# cslr_pllc_001 register map
Vendor: Texas Instruments
Peripheral module from a debugger description file.
Registers are 32-bit, access per field, reset 0x0 unless marked. A register's access mark holds for its fields unless they carry their own. Offsets are as the file gives them; lines under a group give offsets from that group; [hi:lo] are bit positions; {n}, {i} and the like mark numbered series; 'fields as' and 'values as' point back to an identical list; <NAME> marks a mode.

## PLLC — This module propagates reset and clocks to the device
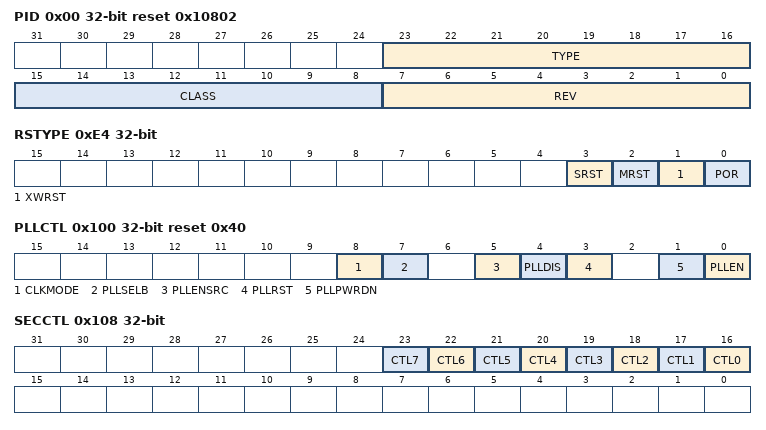
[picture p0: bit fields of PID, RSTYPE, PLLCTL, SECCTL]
0x00 PID ro reset 0x10802 — Contains peripheral ID and revision information
  [23:16] TYPE — Peripheral Type: 0x01 to identify as PLLCTRL
  [15:8] CLASS — Peripheral Class: 0x08
  [7:0] REV — Peripheral Revision
0xE0 FUSERR ro — Stores error code from fusefarm
  [4:0] ERR — Fusefarm Error. Actual default value depends on fusefarm error
0xE4 RSTYPE ro — Latches cause of the last reset. Although the reset value of all bits are 0, after coming out of reset, one bit will be set to one to indicate cause of reset. Some bits may not be doc'd to users.
  [all] fields
    0=NO; 1=YES
  [3] SRST — If 1, means that system reset was the last reset to occur that is of highest priority
  [2] MRST — If 1, means that maximum reset was the reset to occur that is of highest priority
  [1] XWRST — If 1, means that external warm reset was the last reset to occur that is of highest priority
  [0] POR — If 1, means that power on reset was the last reset to occur that is of highest priority
0xE8 RSTDEF — Defines the operation caused by external warm reset pin xwrst_pi_n. May not be documented to users.
  [0] XWFUNC rw — External Warm Reset Definition; May not be documented to users
    0=NORM (Normal mode. External warm reset causes xwrst operation); 1=FAST (Fast mode. External warm reset causes system reset (srst) operation)
0x100 PLLCTL reset 0x40 — Controls PLL operations. Only document necessary bits to users
  [8] CLKMODE rw — Reference Clock Selection; Actual default determined by module tieoff. May lock default value and doc as _RESV to users
    0=OSCIN (Internal oscillator); 1=CLKIN (CLKIN square wave)
  [7] PLLSELB rw — PLL Selection. Actual default determined by module tieoff. May lock default value and doc as _RESV to users
    0=PLLA (PLL A is selected. PLL B in power down); 1=PLLB (PLL B is selected. PLL A in power down)
  [5] PLLENSRC rw — PLLEN mux control source. Actual default determined by module tieoff. May lock default value and doc as _RESV to users
    0=REGBIT (PLLEN mux is controlled by PLLCTL.PLLEN bit); 1=PORT (PLLEN mux is controlled by input pllen_pi)
  [4] PLLDIS rw — Asserts DISABLE to PLL if supported. Actual default determined by module tieoff. If not supported, do not document to users
    0=NO (PLL disable de-asserted); 1=YES (PLL disable asserted)
  [3] PLLRST rw — Asserts RESET to PLL if supported. Actual default determined by module tieoff. If not supported, do not document to users
    0=NO (PLL reset not asserted); 1=YES (PLL reset asserted)
  [1] PLLPWRDN rw — PLL Power down. Actual default determined by module tieoff
    0=NO (PLL operation); 1=YES (PLL power down)
  [0] PLLEN rw — PLL Mode Enable
    0=BYPASS (Bypass mode); 1=PLL (PLL mode, not bypassed)
0x104 OCSEL — Controls the clock that outputs onto OBSCLK. May not need to document to users
  [4:0] OCSRC rw — OBSCLK source. Actual default determined by module tieoff. May not document this bit to users. Even if document may not document all options.
0x108 SECCTL — Extra PLL controls. May not need to document all bits (or the entire register) to users
  [n+16] CTL{n} rw (n=0..7) — PLL Control output. Actual default determined by module tieoff. Maybe documented with more precise bit field name to control a specific PLL
0x110 PLLM — PLL Multiplier Control
  [5:0] PLLM rw — PLL Multiplier Select. Actual default determined by module tieoff. May only document subset to users based on PLL multiply ratios supported
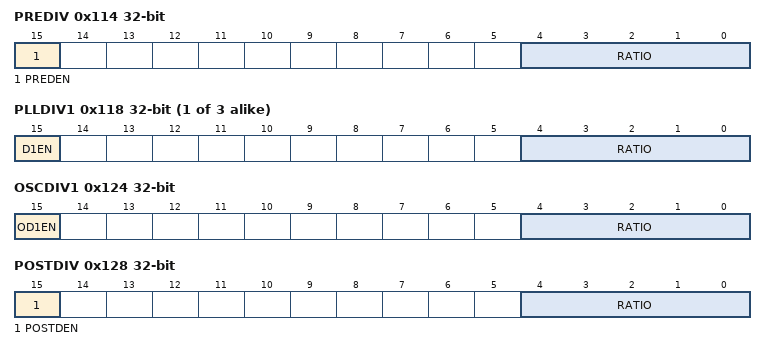
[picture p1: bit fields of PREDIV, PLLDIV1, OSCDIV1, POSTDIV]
0x114 PREDIV — PLL Pre-Divider control. Do not document if Pre-Divider is not implemented
  [15] PREDEN rw — Pre-Divider Enable. Actual default determined by module tieoff.
    0=DISABLE (Pre-div disabled); 1=ENABLE (Pre-div enabled)
  [4:0] RATIO rw — PLL Pre-divider ratio. Actual default determined by module tieoff. May lock default and make bit R only
{0x114+4i} PLLDIV{i} (i=1..3) — Divider {i} control--divider for SYSCLK{i}. Only document if this sysclk exists
  [15] D{i}EN rw — Divider Enable. Actual default determined by module tieoff. May lock default and make bit R only
    0=DISABLE; 1=ENABLE
  [4:0] RATIO rw — Divider ratio. Actual default determined by module tieoff. May lock default and make bit R only
0x124 OSCDIV1 — Oscillator Divider control--divider for OBSCLK functional clock. Only document if this clock exists
  [15] OD1EN rw — Oscillator Divider OD1 enable. Actual default determined by module tieoff
    0=DISABLE; 1=ENABLE
  [4:0] RATIO rw — Divider ratio. Actual default determined by module tieoff.
0x128 POSTDIV — Post-Divider control. Do not document if divider does not exist
  [15] POSTDEN rw — Post-Divider enable. Actual default determined by module tieoff
    0=DISABLE; 1=ENABLE
  [4:0] RATIO rw — Divider ratio. Actual default determined by module tieoff. May lock default and make bit R only
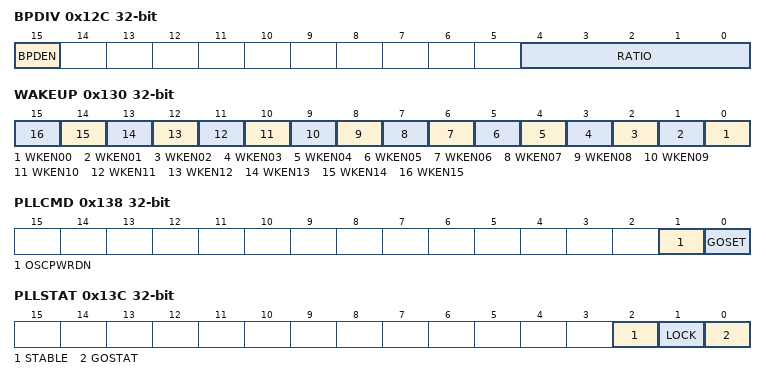
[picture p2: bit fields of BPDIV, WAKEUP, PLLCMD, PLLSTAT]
0x12C BPDIV — bypass divider control--divider for SYSCLKBP. Do not document if clock does not exist
  [15] BPDEN rw — Bypass Divider Enable. Actual default determined by module tieoff
    0=DISABLE; 1=ENABLE
  [4:0] RATIO rw — Divider ratio. Actual default determined by module tieoff.
0x130 WAKEUP — controls events that can wakeup device from oscillator power down. May not document all bits (or entire register) to users.
  [all] fields
    0=DISABLE (pin can't cause wakeup); 1=ENABLE (high on pin can cause wakeup)
  [n] WKEN{n:02} rw (n=0..15) — Wakeup Enable. Input wakeupin{n:02} can wake up device from osc power down.
0x138 PLLCMD — contains command bits for various operations. Writes of 1 initiates command. Writes of 0 clear the bit but have no effect. May not document all bits
  [1] OSCPWRDN rw — Oscillator Power Down Command. May not document if not supported by device
    0=CLRBIT (Clear bit (no effect)); 1=SET (Oscillator Power Down)
  [0] GOSET rw — GO bit for SYSCLKx phase alignment
    0=CLRBIT (Clear bit (no effect)); 1=SET (Phase alignment)
0x13C PLLSTAT ro — shows PLLCTRL status. May not need to document all bits
  [2] STABLE — OSC counter done, oscillator assumed to be stable. By the time device comes out of reset, this bit should become 1. May not need to document
    0=NO; 1=YES
  [1] LOCK — PLL Core Status. If supported, reflects if PLL is locked. Do not document if not supported by PLL
    0=NO; 1=YES
  [0] GOSTAT — Status of GO operation. If 1, indicates GO operation in progress.
    0=NONE; 1=INPROG
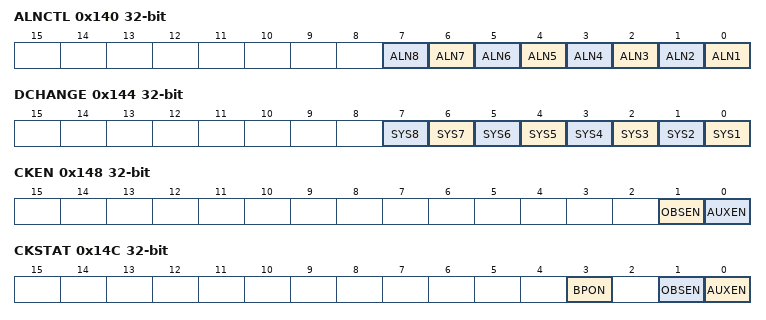
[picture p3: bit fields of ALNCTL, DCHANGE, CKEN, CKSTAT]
0x140 ALNCTL — Indicates which SYSCLKs need to be aligned for proper device operation. May lock defaults and make register R only. Actual default determined by module tieoff. Only document necessary bits
  [all] fields
    0=NO; 1=YES
  [n-1] ALN{n} rw (n=1..8) — SYSCLK{n} needs to be aligned to others selected in this register
0x144 DCHANGE ro — Indicates if SYSCLK divide ratio has been modified. Only document bit if the respective SYSCLK is implemented.
  [all] fields
    0=NO (ratio not modified); 1=YES (ratio modified)
  [n-1] SYS{n} (n=1..8) — SYSCLK{n} divide ratio is modified
0x148 CKEN — clock enable control for miscellaneous output clocks. Only document necessary bits to customers
  [1] OBSEN rw — OBSCLK Enable. Actual default determined by tieoff. May not document to users
    0=DISABLE; 1=ENABLE
  [0] AUXEN rw — AUXCLK enable. Actual default determined by tieoff. Only document if clk exists
    0=DISABLE; 1=ENABLE
0x14C CKSTAT ro — Clock status for all clocks except SYSCLKx. Only document necessary bits to users
  [all] fields
    0=OFF; 1=ON
  [3] BPON — SYSCLKBP on status. Actual default determined by tieoff. Only document if clock exists
  [1] OBSEN — OBSCLK on status. Actual default determined by tieoff. May not document to users
  [0] AUXEN — AUXCLK on status. Actual default determined by tieoff. Only document if clk exists
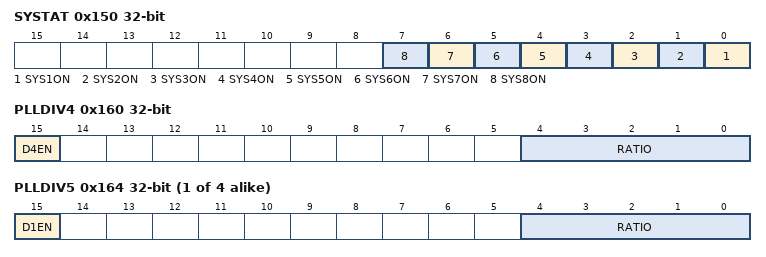
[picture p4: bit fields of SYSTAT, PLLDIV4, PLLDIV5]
0x150 SYSTAT ro — Indicates SYSCLK on/off status. Only document necessary bits to customers. Actual default determined by actual clock on/off status, which depends on PLLDIV[n].D[n]EN bit default
  [all] fields
    0=OFF; 1=ON
  [n-1] SYS{n}ON (n=1..8) — SYSCLK{n} on status
0x160 PLLDIV4 — Divider 4 control--divider for SYSCLK4, Only document if this sysclk exists
  [15] D4EN rw — Divider Enable. Actual default determined by module tieoff. May lock default and make bit R only
    0=DISABLE; 1=ENABLE
  [4:0] RATIO rw — Divider ratio. Actual default determined by module tieoff. May lock default and make bit R only
{0x150+4i} PLLDIV{i} (i=5..8) — Divider {i} control--divider for SYSCLK{i}. Only document if this sysclk exists
  fields as PLLDIV1
